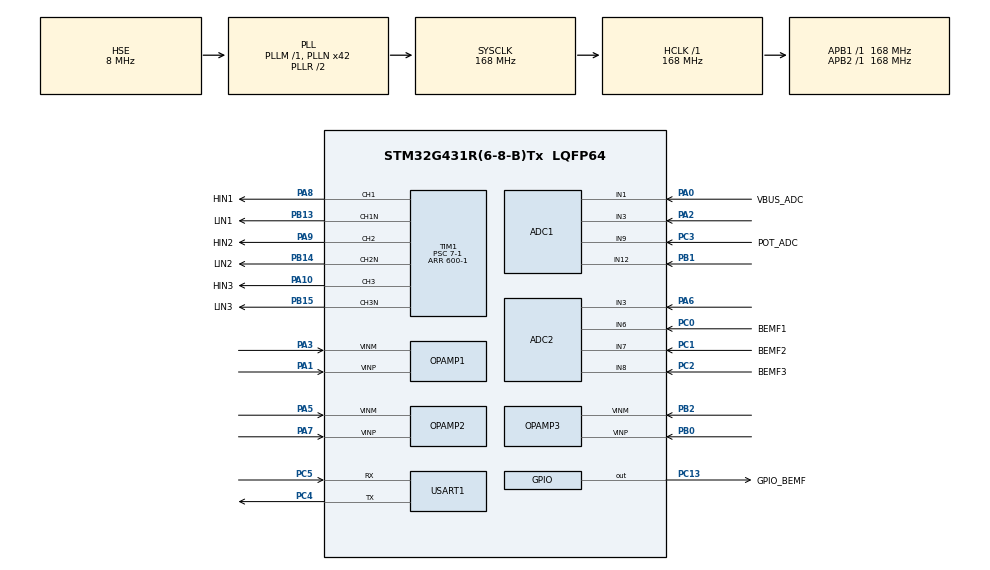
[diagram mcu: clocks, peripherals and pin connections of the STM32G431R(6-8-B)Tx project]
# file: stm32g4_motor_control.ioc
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ADC1.Channel-0\#ChannelRegularConversion=ADC_CHANNEL_1
ADC1.Channel-1\#ChannelRegularConversion=ADC_CHANNEL_9
ADC1.Channel-IN12=ADC_CHANNEL_12
ADC1.Channel-IN3=ADC_CHANNEL_3
ADC1.EnableInjectedConversion=ENABLE
ADC1.EnableInjectedOversampling=DISABLE
ADC1.ExternalTrigInjecConv=ADC_EXTERNALTRIGINJEC_T1_TRGO
ADC1.ExternalTrigInjecConvEdge=ADC_EXTERNALTRIGINJECCONV_EDGE_FALLING
ADC1.EOCSelection=ADC_EOC_SINGLE_CONV
ADC1.InjNumberOfConversion=2
ADC1.InjectedChannel-2\#ChannelInjectedConversion=ADC_CHANNEL_3
ADC1.InjectedChannel-3\#ChannelInjectedConversion=ADC_CHANNEL_12
ADC1.InjectedConvMode=None
ADC1.InjectedOffsetNumber-2\#ChannelInjectedConversion=ADC_OFFSET_NONE
ADC1.InjectedOffsetNumber-3\#ChannelInjectedConversion=ADC_OFFSET_NONE
ADC1.InjectedRank-2\#ChannelInjectedConversion=1
ADC1.InjectedRank-3\#ChannelInjectedConversion=2
ADC1.InjectedSamplingTime-2\#ChannelInjectedConversion=ADC_SAMPLETIME_47CYCLES_5
ADC1.InjectedSamplingTime-3\#ChannelInjectedConversion=ADC_SAMPLETIME_47CYCLES_5
ADC1.NbrOfConversion=2
ADC1.NbrOfConversionFlag=1
ADC1.OffsetNumber-0\#ChannelRegularConversion=ADC_OFFSET_NONE
ADC1.OffsetNumber-1\#ChannelRegularConversion=ADC_OFFSET_NONE
ADC1.Overrun=ADC_OVR_DATA_OVERWRITTEN
ADC1.Rank-0\#ChannelRegularConversion=1
ADC1.Rank-1\#ChannelRegularConversion=2
ADC1.SamplingTime-0\#ChannelRegularConversion=ADC_SAMPLETIME_640CYCLES_5
ADC1.SamplingTime-1\#ChannelRegularConversion=ADC_SAMPLETIME_640CYCLES_5
ADC1.injectedQueueMode=DISABLE
ADC1.master=1
ADC2.Channel-0\#ChannelRegularConversion=ADC_CHANNEL_6
ADC2.Channel-1\#ChannelRegularConversion=ADC_CHANNEL_7
ADC2.Channel-2\#ChannelRegularConversion=ADC_CHANNEL_8
ADC2.Channel-IN3=ADC_CHANNEL_3
ADC2.DMAContinuousRequests=ENABLE
ADC2.EnableInjectedConversion=ENABLE
ADC2.EnableInjectedOversampling=DISABLE
ADC2.ExternalTrigConv=ADC_EXTERNALTRIG_T1_TRGO
ADC2.ExternalTrigConvEdge=ADC_EXTERNALTRIGCONVEDGE_RISING
ADC2.ExternalTrigInjecConv=ADC_EXTERNALTRIGINJEC_T1_TRGO
ADC2.ExternalTrigInjecConvEdge=ADC_EXTERNALTRIGINJECCONV_EDGE_FALLING
ADC2.InjNumberOfConversion=1
ADC2.InjectedChannel-3\#ChannelInjectedConversion=ADC_CHANNEL_3
ADC2.InjectedConvMode=None
ADC2.InjectedOffsetNumber-3\#ChannelInjectedConversion=ADC_OFFSET_NONE
ADC2.InjectedRank-3\#ChannelInjectedConversion=1
ADC2.InjectedSamplingTime-3\#ChannelInjectedConversion=ADC_SAMPLETIME_47CYCLES_5
ADC2.NbrOfConversion=3
ADC2.NbrOfConversionFlag=1
ADC2.OffsetNumber-0\#ChannelRegularConversion=ADC_OFFSET_NONE
ADC2.OffsetNumber-1\#ChannelRegularConversion=ADC_OFFSET_NONE
ADC2.OffsetNumber-2\#ChannelRegularConversion=ADC_OFFSET_NONE
ADC2.Overrun=ADC_OVR_DATA_OVERWRITTEN
ADC2.Rank-0\#ChannelRegularConversion=1
ADC2.Rank-1\#ChannelRegularConversion=2
ADC2.Rank-2\#ChannelRegularConversion=3
ADC2.SamplingTime-0\#ChannelRegularConversion=ADC_SAMPLETIME_47CYCLES_5
ADC2.SamplingTime-1\#ChannelRegularConversion=ADC_SAMPLETIME_47CYCLES_5
ADC2.SamplingTime-2\#ChannelRegularConversion=ADC_SAMPLETIME_47CYCLES_5
ADC2.injectedQueueMode=DISABLE
Dma.ADC2.0.Direction=DMA_PERIPH_TO_MEMORY
Dma.ADC2.0.EventEnable=DISABLE
Dma.ADC2.0.Instance=DMA1_Channel1
Dma.ADC2.0.MemDataAlignment=DMA_MDATAALIGN_HALFWORD
Dma.ADC2.0.MemInc=DMA_MINC_ENABLE
Dma.ADC2.0.Mode=DMA_CIRCULAR
Dma.ADC2.0.PeriphDataAlignment=DMA_PDATAALIGN_HALFWORD
Dma.ADC2.0.PeriphInc=DMA_PINC_DISABLE
Dma.ADC2.0.Polarity=HAL_DMAMUX_REQ_GEN_RISING
Dma.ADC2.0.Priority=DMA_PRIORITY_HIGH
Dma.ADC2.0.RequestNumber=1
Dma.ADC2.0.SignalID=NONE
Dma.ADC2.0.SyncEnable=DISABLE
Dma.ADC2.0.SyncPolarity=HAL_DMAMUX_SYNC_NO_EVENT
Dma.ADC2.0.SyncRequestNumber=1
Dma.ADC2.0.SyncSignalID=NONE
Dma.Request0=ADC2
Mcu.Family=STM32G4
Mcu.Name=STM32G431R(6-8-B)Tx
Mcu.Package=LQFP64
NVIC.ADC1_2_IRQn=true\:0\:0\:false\:false\:true\:true\:true\:true
NVIC.DMA1_Channel1_IRQn=true\:1\:0\:false\:false\:true\:false\:true\:true
NVIC.PriorityGroup=NVIC_PRIORITYGROUP_4
NVIC.USART1_IRQn=true\:3\:0\:false\:false\:true\:true\:true\:true
OPAMP1.PowerMode=OPAMP_POWERMODE_HIGHSPEED
OPAMP2.PowerMode=OPAMP_POWERMODE_HIGHSPEED
OPAMP3.PowerMode=OPAMP_POWERMODE_HIGHSPEED
PA0.GPIO_Label=VBUS_ADC
PA0.Mode=IN1-Single-Ended
PA0.Signal=ADC1_IN1
PA1.Mode=Standalone
PA1.Signal=OPAMP1_VINP
PA10.GPIO_Label=HIN3
PA10.Signal=S_TIM1_CH3
PA13.Mode=Serial_Wire
PA13.Signal=SYS_JTMS-SWDIO
PA14.Mode=Serial_Wire
PA14.Signal=SYS_JTCK-SWCLK
PA2.Signal=SharedAnalog_PA2
PA3.Mode=Standalone
PA3.Signal=OPAMP1_VINM
PA5.Mode=Standalone
PA5.Signal=OPAMP2_VINM
PA6.Signal=SharedAnalog_PA6
PA7.Mode=Standalone
PA7.Signal=OPAMP2_VINP
PA8.GPIO_Label=HIN1
PA8.Signal=S_TIM1_CH1
PA9.GPIO_Label=HIN2
PA9.Signal=S_TIM1_CH2
PB0.Mode=Standalone
PB0.Signal=OPAMP3_VINP
PB1.Signal=SharedAnalog_PB1
PB13.GPIO_Label=LIN1
PB13.Mode=PWM Generation1 CH1 CH1N
PB13.Signal=TIM1_CH1N
PB14.GPIO_Label=LIN2
PB14.Mode=PWM Generation2 CH2 CH2N
PB14.Signal=TIM1_CH2N
PB15.GPIO_Label=LIN3
PB15.Mode=PWM Generation3 CH3 CH3N
PB15.Signal=TIM1_CH3N
PB2.Mode=Standalone
PB2.Signal=OPAMP3_VINM
PC0.GPIO_Label=BEMF1
PC0.Mode=IN6-Single-Ended
PC0.Signal=ADC2_IN6
PC1.GPIO_Label=BEMF2
PC1.Mode=IN7-Single-Ended
PC1.Signal=ADC2_IN7
PC13.GPIO_Label=GPIO_BEMF
PC13.PinState=GPIO_PIN_RESET
PC13.Signal=GPIO_Output
PC2.GPIO_Label=BEMF3
PC2.Mode=IN8-Single-Ended
PC2.Signal=ADC2_IN8
PC3.GPIO_Label=POT_ADC
PC3.Mode=IN9-Single-Ended
PC3.Signal=ADC1_IN9
PC4.GPIO_PuPd=GPIO_NOPULL
PC4.Mode=Asynchronous
PC4.Signal=USART1_TX
PC5.GPIO_PuPd=GPIO_PULLUP
PC5.Mode=Asynchronous
PC5.Signal=USART1_RX
PF0-OSC_IN.Mode=HSE-External-Oscillator
PF0-OSC_IN.Signal=RCC_OSC_IN
PF1-OSC_OUT.Mode=HSE-External-Oscillator
PF1-OSC_OUT.Signal=RCC_OSC_OUT
ProjectManager.HeapSize=0x200
ProjectManager.StackSize=0x400
ProjectManager.TargetToolchain=CMake
RCC.ADC12Freq_Value=168000000
RCC.AHBFreq_Value=168000000
RCC.APB1Freq_Value=168000000
RCC.APB1TimFreq_Value=168000000
RCC.APB2Freq_Value=168000000
RCC.APB2TimFreq_Value=168000000
RCC.CortexFreq_Value=168000000
RCC.EXTERNAL_CLOCK_VALUE=12288000
RCC.HCLKFreq_Value=168000000
RCC.HSE_VALUE=8000000
RCC.HSI48_VALUE=48000000
RCC.HSI_VALUE=16000000
RCC.LSE_VALUE=32768
RCC.PLLN=42
RCC.PLLSourceVirtual=RCC_PLLSOURCE_HSE
RCC.SYSCLKFreq_VALUE=168000000
RCC.SYSCLKSource=RCC_SYSCLKSOURCE_PLLCLK
RCC.USBFreq_Value=168000000
RCC.VCOOutputFreq_Value=336000000
SH.S_TIM1_CH1.0=TIM1_CH1,PWM Generation1 CH1 CH1N
SH.S_TIM1_CH2.0=TIM1_CH2,PWM Generation2 CH2 CH2N
SH.S_TIM1_CH3.0=TIM1_CH3,PWM Generation3 CH3 CH3N
SH.SharedAnalog_PA2.0=ADC1_IN3,IN3-Single-Ended
SH.SharedAnalog_PA2.1=OPAMP1_VOUT,Standalone
SH.SharedAnalog_PA6.0=ADC2_IN3,IN3-Single-Ended
SH.SharedAnalog_PA6.1=OPAMP2_VOUT,Standalone
SH.SharedAnalog_PB1.0=ADC1_IN12,IN12-Single-Ended
SH.SharedAnalog_PB1.1=OPAMP3_VOUT,Standalone
TIM1.AutoReloadPreload=TIM_AUTORELOAD_PRELOAD_ENABLE
TIM1.Channel-PWM\ Generation1\ CH1\ CH1N=TIM_CHANNEL_1
TIM1.Channel-PWM\ Generation2\ CH2\ CH2N=TIM_CHANNEL_2
TIM1.Channel-PWM\ Generation3\ CH3\ CH3N=TIM_CHANNEL_3
TIM1.Channel-PWM\ Generation4\ No\ Output=TIM_CHANNEL_4
TIM1.CounterMode=TIM_COUNTERMODE_CENTERALIGNED1
TIM1.DeadTime=50
TIM1.OCNIdleState_1=TIM_OCNIDLESTATE_RESET
TIM1.OCNIdleState_2=TIM_OCNIDLESTATE_RESET
TIM1.OCNIdleState_3=TIM_OCNIDLESTATE_RESET
TIM1.OCNPolarity_1=TIM_OCNPOLARITY_HIGH
TIM1.OCNPolarity_2=TIM_OCNPOLARITY_HIGH
TIM1.OCNPolarity_3=TIM_OCNPOLARITY_HIGH
TIM1.OCMode_PWM-PWM\ Generation4\ No\ Output=TIM_OCMODE_PWM1
TIM1.PeriodNoDither=600-1
TIM1.Prescaler=7-1
TIM1.PulseNoDither_4=80
TIM1.TIM_MasterOutputTrigger=TIM_TRGO_OC4REF
TIM2.AutoReloadPreload=TIM_AUTORELOAD_PRELOAD_ENABLE
TIM2.Prescaler=168-1
TIM6.AutoReloadPreload=TIM_AUTORELOAD_PRELOAD_DISABLE
TIM6.Period=65535
TIM6.Prescaler=168-1
USART1.VirtualMode-Asynchronous=VM_ASYNC
VP_SYS_VS_DBSignals.Mode=DisableDeadBatterySignals
VP_TIM1_VS_ClockSourceINT.Mode=Internal
VP_TIM1_VS_no_output4.Mode=PWM Generation4 No Output
VP_TIM2_VS_ClockSourceINT.Mode=Internal
VP_TIM6_VS_ClockSourceINT.Mode=Enable_Timer
board=custom

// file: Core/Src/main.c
/* USER CODE BEGIN Header */
/**
  ******************************************************************************
  * @file           : main.c
  * @brief          : Main program body
  ******************************************************************************
  * @attention
  *
  * Copyright (c) 2026 STMicroelectronics.
  * All rights reserved.
  *
  * This software is licensed under terms that can be found in the LICENSE file
  * in the root directory of this software component.
  * If no LICENSE file comes with this software, it is provided AS-IS.
  *
  ******************************************************************************
  */
/* USER CODE END Header */
#include "main.h"
#include "adc.h"
#include "dma.h"
#include "opamp.h"
#include "tim.h"
#include "usart.h"
#include "gpio.h"

/* USER CODE BEGIN Includes */
#include "hjf_mcpwm.h"
/* USER CODE END Includes */

void SystemClock_Config(void);

int main(void)
{

  /* MCU Configuration--------------------------------------------------------*/

  /* Reset of all peripherals, Initializes the Flash interface and the Systick. */
  HAL_Init();

  /* Configure the system clock */
  SystemClock_Config();

  /* Initialize all configured peripherals */
  MX_GPIO_Init();
  MX_DMA_Init();
  MX_ADC2_Init();
  MX_ADC1_Init();
  MX_TIM1_Init();
  MX_TIM6_Init();
  MX_OPAMP1_Init();
  MX_OPAMP2_Init();
  MX_OPAMP3_Init();
  MX_USART1_UART_Init();
  MX_TIM2_Init();
  /* USER CODE BEGIN 2 */

  BLDC_SetCurrentScalePermille(1000U, 1000U, 1000U); /* 三相先使用标称电流增益，实测后分别校准。 */
  BLDC_SetOvercurrentLimitMa(1200); /* 长时间温升测试使用一点二安软件过流保护。 */
  BLDC_SetInputCurrentLimitMa(600U); /* 按 VESC BLDC 估算方式限制母线输入电流为六百毫安。 */
  BLDC_SetInputPowerLimitMw(15000U); /* 将母线输入功率限制为十五瓦。 */
  BLDC_SetMotorCurrentLimitMa(1100); /* 将统一电机电流上限设置为一点一安。 */
  BLDC_SetDutyLimitsPermille(84U, 500U); /* 将电流环 PWM 计数范围限制为约百分之八点四到百分之五十。 */
  BLDC_SetSpeedLimitsErpm(1500U, 6500U); /* 将当前实机验证速度范围限制为一千五百到六千五百电角转每分钟。 */
  BLDC_SetSpeedPidGains(50U, 1000U, 0U, 200U); /* 设置速度 PID 为原速度 PI 等效增益并暂时关闭微分项。 */
  BLDC_SetPhaseAdvanceMaxPermille(100U); /* 纯积分闭环在高速区最多提前百分之十的积分阈值。 */
  BLDC_test(); /* 初始化 VESC 风格非同步整流无感 Integrate 控制。 */
  BLDC_SetCurrentRampMaPerSecond(500U, 1000U); /* 运行命令每秒上升零点五安、下降一安。 */
  BLDC_SetSignedSpeedErpm(6200); /* 默认正转六千二百电角转每分钟，改为负数可请求自动安全换向。 */
  /* 电流模式测试时只把上一行替换为 BLDC_SetRunCurrentMa(400)，该命令会持续产生四百毫安转矩。 */
  /* 占空比模式测试时只把上一行替换为 BLDC_SetDutyPermille(320U)，不要同时调用两个模式。 */

  /* USER CODE END 2 */

  /* Infinite loop */
  while (1)
  {

    /* USER CODE BEGIN 3 */
    BLDC_Process(); /* 持续执行母线保护、软停机和失步自动恢复管理。 */
  }
  /* USER CODE END 3 */
}

void SystemClock_Config(void)
{
  RCC_OscInitTypeDef RCC_OscInitStruct = {0};
  RCC_ClkInitTypeDef RCC_ClkInitStruct = {0};

  /** Configure the main internal regulator output voltage
  */
  HAL_PWREx_ControlVoltageScaling(PWR_REGULATOR_VOLTAGE_SCALE1_BOOST);

  /** Initializes the RCC Oscillators according to the specified parameters
  * in the RCC_OscInitTypeDef structure.
  */
  RCC_OscInitStruct.OscillatorType = RCC_OSCILLATORTYPE_HSE;
  RCC_OscInitStruct.HSEState = RCC_HSE_ON;
  RCC_OscInitStruct.PLL.PLLState = RCC_PLL_ON;
  RCC_OscInitStruct.PLL.PLLSource = RCC_PLLSOURCE_HSE;
  RCC_OscInitStruct.PLL.PLLM = RCC_PLLM_DIV1;
  RCC_OscInitStruct.PLL.PLLN = 42;
  RCC_OscInitStruct.PLL.PLLP = RCC_PLLP_DIV2;
  RCC_OscInitStruct.PLL.PLLQ = RCC_PLLQ_DIV2;
  RCC_OscInitStruct.PLL.PLLR = RCC_PLLR_DIV2;
  if (HAL_RCC_OscConfig(&RCC_OscInitStruct) != HAL_OK)
  {
    Error_Handler();
  }

  /** Initializes the CPU, AHB and APB buses clocks
  */
  RCC_ClkInitStruct.ClockType = RCC_CLOCKTYPE_HCLK|RCC_CLOCKTYPE_SYSCLK
                              |RCC_CLOCKTYPE_PCLK1|RCC_CLOCKTYPE_PCLK2;
  RCC_ClkInitStruct.SYSCLKSource = RCC_SYSCLKSOURCE_PLLCLK;
  RCC_ClkInitStruct.AHBCLKDivider = RCC_SYSCLK_DIV1;
  RCC_ClkInitStruct.APB1CLKDivider = RCC_HCLK_DIV1;
  RCC_ClkInitStruct.APB2CLKDivider = RCC_HCLK_DIV1;

  if (HAL_RCC_ClockConfig(&RCC_ClkInitStruct, FLASH_LATENCY_4) != HAL_OK)
  {
    Error_Handler();
  }
}

void Error_Handler(void)
{
  __disable_irq();
  while (1)
  {
  }
}
